# DDRSS0_CTL_CFG register map
Vendor: Texas Instruments
Peripheral module from a debugger description file (folder am65x).
Registers are 32-bit, read-write, reset 0x0 unless marked. A register's access mark holds for its fields unless they carry their own. Offsets are as the file gives them; lines under a group give offsets from that group; [hi:lo] are bit positions; {n}, {i} and the like mark numbered series; 'fields as' and 'values as' point back to an identical list; <NAME> marks a mode.

## DDRSS0_CTL_CFG (part 1 of 2)
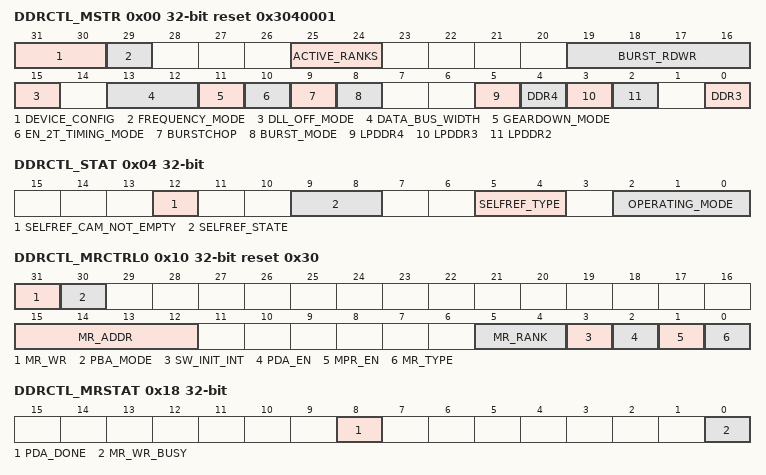
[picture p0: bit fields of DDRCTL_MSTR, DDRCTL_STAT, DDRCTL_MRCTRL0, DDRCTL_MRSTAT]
0x00 DDRCTL_MSTR reset 0x3040001 — Master Register0
  [31:30] DEVICE_CONFIG — Indicates the configuration of the device used in the system.
  [29] FREQUENCY_MODE — Choose which registers are used.1 - FREQ1 registersProgramming Mode: Quasi-dynamic Group 2
  [25:24] ACTIVE_RANKS — Only present for multi-rank configurations.LSB is the lowest rank number. For 2 ranks following combinations are legal:For 4 ranks following combinations are legal:
  [19:16] BURST_RDWR — SDRAM burst length used:
  [15] DLL_OFF_MODE — Set to 1 when the DDR controller and DRAM has to be put in DLL-off mode for low frequency operation.
  [13:12] DATA_BUS_WIDTH — Selects proportion of DQ bus width that is used by the SDRAM
  [11] GEARDOWN_MODE — 1 - Put the DRAM in geardown mode (2N)0 - Put the DRAM in normal mode (1N)This register can be changed, only when the Controller is in self-refresh mode. This signal must be set the same value as MR3 bit A3.
  [10] EN_2T_TIMING_MODE — If 1, then DDR controller uses 2T timing. Otherwise, uses 1T timing. In 2T timing, all command signals (except chip select) are held for 2 clocks on the SDRAM bus. Chip select is asserted on the second cycle of the command
  [9] BURSTCHOP — When set, enable burst-chop (BC4 or 8 on-the-fly) in DDR3/DDR4.
  [8] BURST_MODE — Indicates burst mode.
  [5] LPDDR4 — Select LPDDR4 SDRAM
  [4] DDR4 — Select DDR4 SDRAM
  [3] LPDDR3 — Select LPDDR3 SDRAM
  [2] LPDDR2 — Select LPDDR2 SDRAM
  [0] DDR3 — Select DDR3 SDRAM
0x04 DDRCTL_STAT ro — Operating Mode Status Register
  [12] SELFREF_CAM_NOT_EMPTY — Self refresh with CAMs not empty.
  [9:8] SELFREF_STATE — Self refresh state.
  [5:4] SELFREF_TYPE — Flags if Self Refresh (except LPDDR4) or SR-Powerdown (LPDDR4) is entered and if it was under Automatic Self Refresh control only or not.
  [2:0] OPERATING_MODE — Operating mode.mDDR/LPDDR2/LPDDR3 or DDR4 designs:LPDDR4 designs:
0x10 DDRCTL_MRCTRL0 access not given reset 0x30 — Mode Register Read/Write Control Register 0. Note: Do not enable more than one of the following fields simultaneously: - sw_init_int - pda_en - mpr_en
  [31] MR_WR — Setting this register bit to 1 triggers a mode register read or write operation. (access W1S)
  [30] PBA_MODE rw — Indicates whether PBA access is executed.
  [15:12] MR_ADDR rw — Address of the mode register that is to be written to.Don't Care for LPDDR2/LPDDR3/LPDDR4 (see DDRCTL_MRCTRL1.mr_data for mode register addressing in LPDDR2/LPDDR3/LPDDR4).This signal is also used for writing to control words of the register chip on RDIMMs/LRDIMMs. In that case, it corresponds to the bank address bits sent to the RDIMM/LRDIMM In case of DDR4, the bit [3:2] corresponds to the bank group bits. Therefore, the bit[3] as well as the bit [2:0] must be set to an appropriate value which is considered both the Address Mirroring of UDIMMs/RDIMMs/LRDIMMs and the Output Inversion of RDIMMs/LRDIMMs.
  [5:4] MR_RANK rw — Controls which rank is accessed by DDRCTL_MRCTRL0.mr_wr.Normally, it is desired to access all ranks, so all bits should be set to 1. However, for multi-rank UDIMMs/RDIMMs/LRDIMMs which implement address mirroring, it may be necessary to access ranks individually. Examples (assume DDR controller is configured for 4 ranks):
  [3] SW_INIT_INT rw — Indicates whether Software intervention is allowed via DDRCTL_MRCTRL0/DDRCTL_MRCTRL1 before automatic SDRAM initialization routine or not.
  [2] PDA_EN rw — Indicates whether the mode register operation is MRS in PDA mode or not
  [1] MPR_EN rw — Indicates whether the mode register operation is MRS or WR/RD for MPR (only supported for DDR4)
  [0] MR_TYPE rw — Indicates whether the mode register operation is read or write.
0x14 DDRCTL_MRCTRL1 — Mode Register Read/Write Control Register 1
  [17:0] MR_DATA — Mode register write data for all non-LPDDR2/non-LPDDR3/non-LPDDR4 modes.
0x18 DDRCTL_MRSTAT ro — Mode Register Read/Write Status Register
  [8] PDA_DONE — The SoC core may initiate a MR write operation in PDA/PBA mode only if this signal is low.
  [0] MR_WR_BUSY — The SoC core may initiate a MR write operation only if this signal is low.
0x1C DDRCTL_MRCTRL2 — Mode Register Read/Write Control Register 2
  [31:0] MR_DEVICE_SEL — Indicates the device(s) to be selected during the MRS that happens in PDA mode.
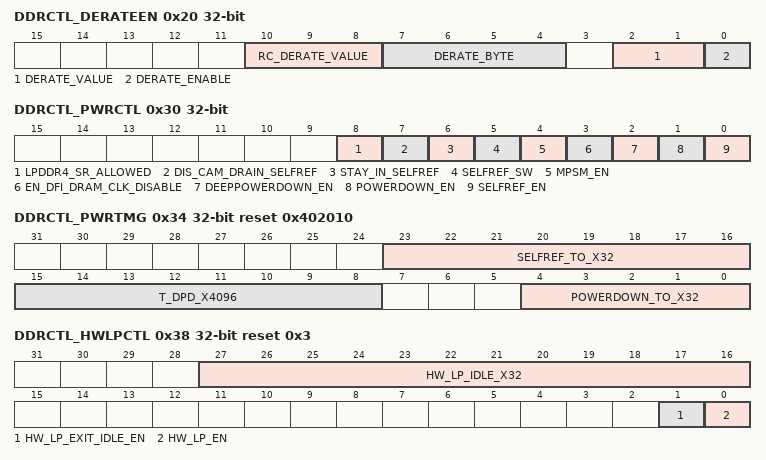
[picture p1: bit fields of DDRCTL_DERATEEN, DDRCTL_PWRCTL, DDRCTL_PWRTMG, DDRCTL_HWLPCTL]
0x20 DDRCTL_DERATEEN — Temperature Derate Enable Register
  [10:8] RC_DERATE_VALUE — Derate value of tRC for LPDDR4Present only in designs configured to support LPDDR4. The required number of cycles for derating can be determined by dividing 3.75ns by the core_ddrc_core_clk period, and rounding up the next integer.
  [7:4] DERATE_BYTE — Derate bytePresent only in designs configured to support LPDDR2/LPDDR3/LPDDR4Indicates which byte of the MRR data is used for derating.
  [2:1] DERATE_VALUE — Derate valuePresent only in designs configured to support LPDDR2/LPDDR3/LPDDR4 Set to 0 for all LPDDR2 speed grades as derating value of +1.875 ns is less than a core_ddrc_core_clk period. For LPDDR3/4, if the period of core_ddrc_core_clk is less than 1.875ns, this register field should be set to 1 otherwise it should be set to 0.
  [0] DERATE_ENABLE — Enables derating
0x24 DDRCTL_DERATEINT reset 0x800000 — Temperature Derate Interval Register
  [31:0] MR4_READ_INTERVAL — Interval between two MR4 reads, used to derate the timing parameters.
0x30 DDRCTL_PWRCTL — Low Power Control Register
  [8] LPDDR4_SR_ALLOWED — Indicates whether transition from SR-PD to SR and back to SR-PD is allowed.
  [7] DIS_CAM_DRAIN_SELFREF — Indicates whether skipping CAM draining is allowed when entering Self-Refresh.
  [6] STAY_IN_SELFREF — Self refresh state is an intermediate state to enter to Self refresh power down state or exit Self refresh power down state for LPDDR4.
  [5] SELFREF_SW — A value of 1 to this register causes system to move to Self Refresh state immediately, as long as it is not in INIT or DPD/MPSM operating_mode.
  [4] MPSM_EN — When this is 1, the DDR controller puts the SDRAM into maximum power saving mode when the transaction store is empty.
  [3] EN_DFI_DRAM_CLK_DISABLE — Enable the assertion of dfi_dram_clk_disable whenever a clock is not required by the SDRAM.In DDR2/DDR3, can only be asserted in Self Refresh.In DDR4, can be asserted in following:- in Self Refresh.- in Maximum Power Saving ModeIn mDDR/LPDDR2/LPDDR3, can be asserted in following:- in Self Refresh- in Power Down- in Deep Power Down- during Normal operation (Clock Stop)In LPDDR4, can be asserted in following:- in Self Refresh Power Down- in Power Down- during Normal operation (Clock Stop)
  [2] DEEPPOWERDOWN_EN — When this is 1, DDR controller puts the SDRAM into deep power-down mode when the transaction store is empty.For non-mDDR/non-LPDDR2/non-LPDDR3, this register should not be set to 1.
  [1] POWERDOWN_EN — If true then the DDR controller goes into power-down after a programmable number of cycles 'maximum idle clocks before power down' (DDRCTL_PWRTMG.powerdown_to_x32).This register bit may be re-programmed during the course of normal operation.
  [0] SELFREF_EN — If true then the DDR controller puts the SDRAM into Self Refresh after a programmable number of cycles 'maximum idle clocks before Self Refresh (DDRCTL_PWRTMG.selfref_to_x32)'.This register bit may be re-programmed during the course of normal operation.
0x34 DDRCTL_PWRTMG reset 0x402010 — Low Power Timing Register
  [23:16] SELFREF_TO_X32 — After this many clocks of the DDRC command channel being idle the DDR controller automatically puts the SDRAM into Self Refresh.
  [15:8] T_DPD_X4096 — Minimum deep power-down time.
  [4:0] POWERDOWN_TO_X32 — After this many clocks of the DDRC command channel being idle the DDR controller automatically puts the SDRAM into power-down.
0x38 DDRCTL_HWLPCTL reset 0x3 — Hardware Low Power Control Register
  [27:16] HW_LP_IDLE_X32 — Hardware idle period.
  [1] HW_LP_EXIT_IDLE_EN — When this bit is programmed to 1 the cactive_in_ddrc pin of the DDRC can be used to exit from the automatic clock stop, automatic power down or automatic self-refresh modes.
  [0] HW_LP_EN — Enable for Hardware Low Power Interface.
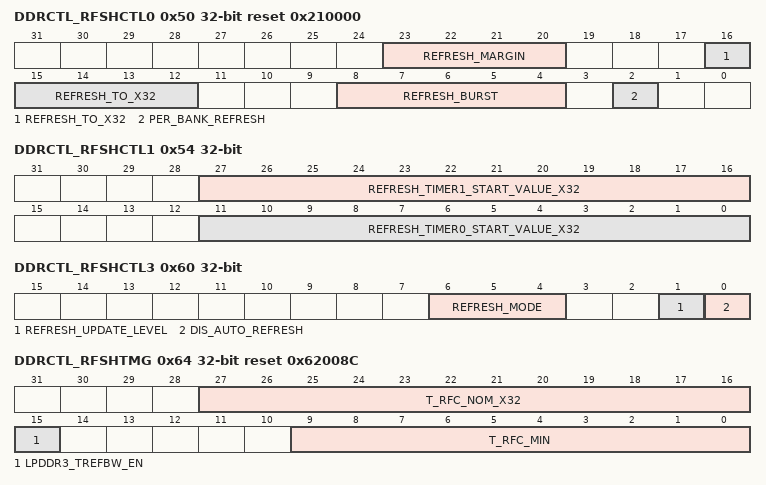
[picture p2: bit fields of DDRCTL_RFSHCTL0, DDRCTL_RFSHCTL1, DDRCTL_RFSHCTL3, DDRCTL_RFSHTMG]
0x50 DDRCTL_RFSHCTL0 reset 0x210000 — Refresh Control Register 0
  [23:20] REFRESH_MARGIN — Threshold value in number of DDRSS_CTL_CLK clock cycles before the critical refresh or page timer expires.
  [16:12] REFRESH_TO_X32 — If the refresh timer (tRFCnom, also known as tREFI) has expired at least once, but it has not expired (DDRCTL_RFSHCTL0.refresh_burst+1) times yet, then a speculative refresh may be performed. A speculative refresh is a refresh performed at a time when refresh would be useful, but before it is absolutely required.
  [8:4] REFRESH_BURST — The programmed value + 1 is the number of refresh timeouts that is allowed to accumulate before traffic is blocked and the refreshes are forced to execute.For information on burst refresh feature refer to section 3.9 of DDR2 JEDEC specification - JESD79-2F.pdf. For DDR2/3, the refresh is always per-rank and not per-bank. The rank refresh can be accumulated over 8*tREFI cycles using the burst refresh feature. In DDR4 mode, according to Fine Granularity feature, 8 refreshes can be postponed in 1X mode, 16 refreshes in 2X mode and 32 refreshes in 4X mode. If using PHY-initiated updates, care must be taken in the setting of DDRCTL_RFSHCTL0.refresh_burst, to ensure that tRFCmax is not violated due to a PHY-initiated update occurring shortly before a refresh burst was due. In this situation, the refresh burst will be delayed until the PHY-initiated update is complete.
  [2] PER_BANK_REFRESH — 1 - Per bank refresh
0x54 DDRCTL_RFSHCTL1 — Refresh Control Register 1
  [27:16] REFRESH_TIMER1_START_VALUE_X32 — Refresh timer start for rank 1 (only present in multi-rank configurations).
  [11:0] REFRESH_TIMER0_START_VALUE_X32 — Refresh timer start for rank 0 (only present in multi-rank configurations).
0x60 DDRCTL_RFSHCTL3 — Refresh Control Register 3
  [6:4] REFRESH_MODE — Fine Granularity Refresh Mode
  [1] REFRESH_UPDATE_LEVEL — Toggle this signal (either from 0 to 1 or from 1 to 0) to indicate that the refresh register(s) have been updated.
  [0] DIS_AUTO_REFRESH — When '1', disable auto-refresh generated by the DDR controller.
0x64 DDRCTL_RFSHTMG reset 0x62008C — Refresh Timing Register
  [27:16] T_RFC_NOM_X32 — tREFI: Average time interval between refreshes per rank (Specification: 7.8us for DDR2, DDR3 and DDR4. See JEDEC specification for mDDR, LPDDR2, LPDDR3 and LPDDR4).For LPDDR2/LPDDR3/LPDDR4:- if using all-bank refreshes (DDRCTL_RFSHCTL0.per_bank_refresh = 0), this register should be set to tREFIab- if using per-bank refreshes (DDRCTL_RFSHCTL0.per_bank_refresh = 1), this register should be set to tREFIpb
  [15] LPDDR3_TREFBW_EN — Used only when LPDDR3 memory type is connected.
  [9:0] T_RFC_MIN — tRFC (min): Minimum time from refresh to refresh or activate.In LPDDR2/LPDDR3/LPDDR4 mode:- if using all-bank refreshes, the tRFCmin value in the above equations is equal to tRFCab- if using per-bank refreshes, the tRFCmin value in the above equations is equal to tRFCpbIn DDR4 mode, the tRFCmin value in the above equations is different depending on the refresh mode (fixed 1X,2X,4X) and the device density. The user should program the appropriate value from the spec based on the 'refresh_mode' and the device density that is used. Unit: Clocks.
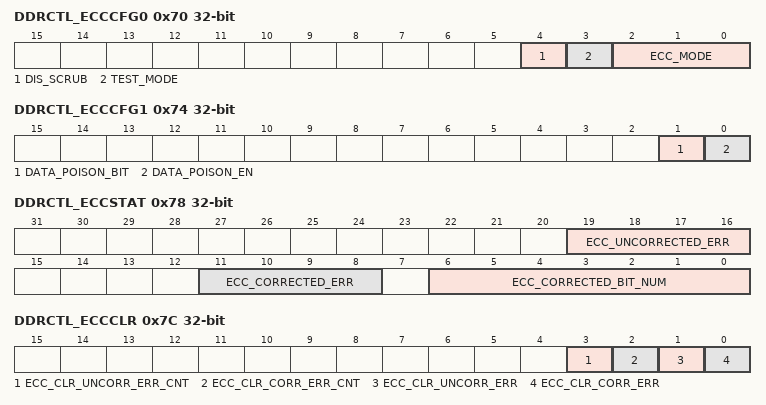
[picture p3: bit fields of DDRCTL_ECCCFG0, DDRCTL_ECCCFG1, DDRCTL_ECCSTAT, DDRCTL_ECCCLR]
0x70 DDRCTL_ECCCFG0 — ECC Configuration Register 0
  [4] DIS_SCRUB — Disable ECC scrubs.
  [3] TEST_MODE — If this bit is set to 1, no ECC is performed, and the ECC byte is accessed directly from co_wu_rxdata_ecc and ra_co_resp_ecc_data.
  [2:0] ECC_MODE — ECC mode indicator
0x74 DDRCTL_ECCCFG1 — ECC Configuration Register 1
  [1] DATA_POISON_BIT — Selects whether to poison 1 or 2 bitsif 0 -&gt; 2-bit (uncorrectable) data poisoning,if 1 -&gt; 1-bit (correctable) data poisoning, if DDRCTL_ECCCFG1.data_poison_en=1.Programming Mode: Quasi-dynamic Group 3
  [0] DATA_POISON_EN — Enable ECC data poisoning - introduces ECC errors on writes to address specified by the DDRCTL_ECCPOISONADDR0/1 registers
0x78 DDRCTL_ECCSTAT ro — SECDED ECC Status Register
  [19:16] ECC_UNCORRECTED_ERR — Double-bit error indicators.
  [11:8] ECC_CORRECTED_ERR — Single-bit error indicators.
  [6:0] ECC_CORRECTED_BIT_NUM — Bit number corrected by single-bit ECC error.
0x7C DDRCTL_ECCCLR access not given — ECC Clear Register
  [3] ECC_CLR_UNCORR_ERR_CNT — Setting this register bit to 1 clears the currently stored uncorrected ECC error count. (access RW1C)
  [2] ECC_CLR_CORR_ERR_CNT — Setting this register bit to 1 clears the currently stored corrected ECC error count. (access RW1C)
  [1] ECC_CLR_UNCORR_ERR — Setting this register bit to 1 clears the currently stored uncorrected ECC error. (access RW1C)
  [0] ECC_CLR_CORR_ERR — Setting this register bit to 1 clears the currently stored corrected ECC error. (access RW1C)
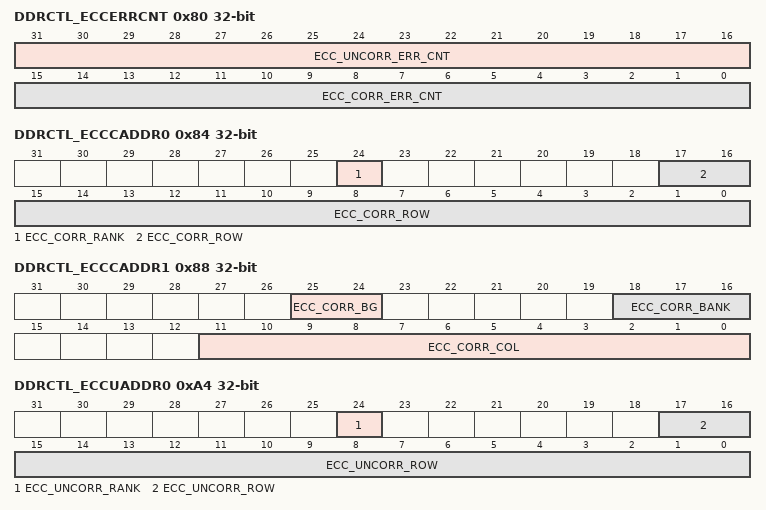
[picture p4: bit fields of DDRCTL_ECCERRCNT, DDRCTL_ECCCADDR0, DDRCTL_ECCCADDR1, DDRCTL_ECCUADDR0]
0x80 DDRCTL_ECCERRCNT ro — ECC Error Counter Register
  [31:16] ECC_UNCORR_ERR_CNT — Number of uncorrectable ECC errors detected.
  [15:0] ECC_CORR_ERR_CNT — Number of correctable ECC errors detected.
0x84 DDRCTL_ECCCADDR0 ro — ECC Corrected Error Address Register 0
  [24] ECC_CORR_RANK — Rank number of a read resulting in a corrected ECC error
  [17:0] ECC_CORR_ROW — Page/row number of a read resulting in a corrected ECC error.
0x88 DDRCTL_ECCCADDR1 ro — ECC Corrected Error Address Register 1
  [25:24] ECC_CORR_BG — Bank Group number of a read resulting in a corrected ECC error
  [18:16] ECC_CORR_BANK — Bank number of a read resulting in a corrected ECC error
  [11:0] ECC_CORR_COL — Block number of a read resulting in a corrected ECC error (lowest bit not assigned here)
0x8C DDRCTL_ECCCSYN0 ro — ECC Corrected Syndrome Register 0
  [31:0] ECC_CORR_SYNDROMES_31_0 — Data pattern that resulted in a corrected error.
0x94 DDRCTL_ECCCSYN2 ro — ECC Corrected Syndrome Register 2
  [7:0] ECC_CORR_SYNDROMES_71_64 — Data pattern that resulted in a corrected error one for each ECC lane, all concatenated together This register refers to the ECC byte, which is bits [71:64] for 64-bit ECC, [39:32] for 32-bit ECC, or [23:16] for 16-bit ECC
0x98 DDRCTL_ECCBITMASK0 ro — ECC Corrected Data Bit Mask Register 0
  [31:0] ECC_CORR_BIT_MASK_31_0 — Mask for the corrected data portion1 on any bit indicates that the bit has been corrected by the ECC logic0 on any bit indicates that the bit has not been corrected by the ECC logicThis register accumulates data over multiple ECC errors, to give an overall indication of which bits are being fixed.
0xA0 DDRCTL_ECCBITMASK2 ro — ECC Corrected Data Bit Mask Register 2
  [7:0] ECC_CORR_BIT_MASK_71_64 — Mask for the corrected data portion1 on any bit indicates that the bit has been corrected by the ECC logic0 on any bit indicates that the bit has not been corrected by the ECC logicThis register accumulates data over multiple ECC errors, to give an overall indication of which bits are being fixed.
0xA4 DDRCTL_ECCUADDR0 ro — ECC Uncorrected Error Address Register 0
  [24] ECC_UNCORR_RANK — Rank number of a read resulting in an uncorrected ECC error
  [17:0] ECC_UNCORR_ROW — Page/row number of a read resulting in an uncorrected ECC error.
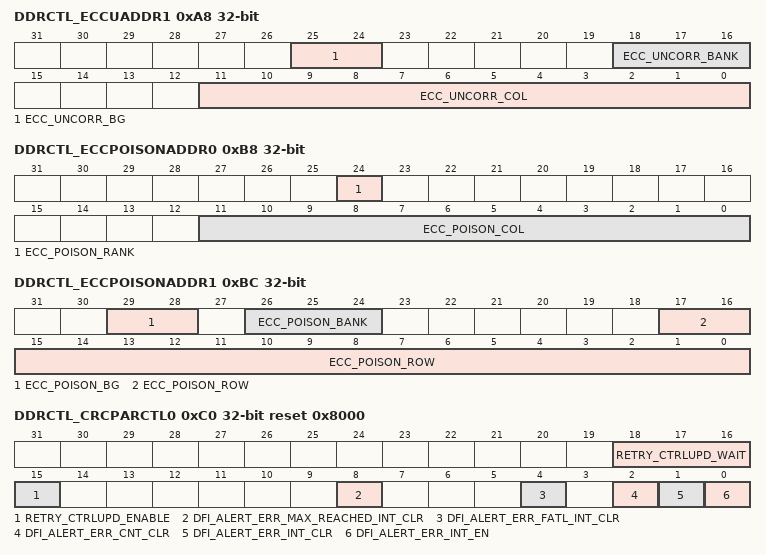
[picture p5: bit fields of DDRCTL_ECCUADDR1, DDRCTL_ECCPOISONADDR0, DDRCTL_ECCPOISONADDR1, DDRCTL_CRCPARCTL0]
0xA8 DDRCTL_ECCUADDR1 ro — ECC Uncorrected Error Address Register 1
  [25:24] ECC_UNCORR_BG — Bank Group number of a read resulting in an uncorrected ECC error
  [18:16] ECC_UNCORR_BANK — Bank number of a read resulting in an uncorrected ECC error
  [11:0] ECC_UNCORR_COL — Block number of a read resulting in an uncorrected ECC error (lowest bit not assigned here)
0xAC DDRCTL_ECCUSYN0 ro — ECC Uncorrected Syndrome Register 0
  [31:0] ECC_UNCORR_SYNDROMES_31_0 — Data pattern that resulted in an uncorrected error, one for each ECC lane, all concatenated together.
0xB4 DDRCTL_ECCUSYN2 ro — ECC Uncorrected Syndrome Register 2
  [7:0] ECC_UNCORR_SYNDROMES_71_64 — Data pattern that resulted in an uncorrected error one for each ECC lane, all concatenated together.
0xB8 DDRCTL_ECCPOISONADDR0 — ECC Data Poisoning Address Register 0. If a HIF write data beat matches the address specified in this register, an ECC error will be introduced on that transaction (write/RMW), if DDRCTL_ECCCFG1.data_poison_en=1
  [24] ECC_POISON_RANK — Rank address for ECC poisoning
  [11:0] ECC_POISON_COL — Column address for ECC poisoning.- In full bus width mode, ecc_poison_col [2:0] must be set to 0- In half bus width mode, ecc_poison_col [3:0] must be set to 0- In quarter bus width mode, ecc_poison_col [4:0] must be set to 0
0xBC DDRCTL_ECCPOISONADDR1 — ECC Data Poisoning Address Register 1. If a HIF write data beat matches the address specified in this register, an ECC error will be introduced on that transaction (write/RMW), if DDRCTL_ECCCFG1.data_poison_en=1
  [29:28] ECC_POISON_BG — Bank Group address for ECC poisoning
  [26:24] ECC_POISON_BANK — Bank address for ECC poisoning
  [17:0] ECC_POISON_ROW — Row address for ECC poisoning.
0xC0 DDRCTL_CRCPARCTL0 access not given reset 0x8000 — CRC Parity Control Register0
  [18:16] RETRY_CTRLUPD_WAIT rw — Additional wait time after dfi_ctrlupd_req for retry has occurred to ensure PHY's internals (FIFO pointers) have been reset correctly.
  [15] RETRY_CTRLUPD_ENABLE rw — dfi_ctrlupd_req enable for retry.0 - Disable to issue dfi_ctrlupd_req before starting retry sequenceThe DFI controller update can be used to reset PHY FIFO pointers. If both DDRCTL_CRCPARCTL0.retry_cfrlupd_enable and DDRCTL_CRCPARCTL1.alert_wait_for_sw are enabled, dfi_ctrlupd_req is issued just before software intervention time. If DDRCTL_CRCPARCTL0.retry_cfrlupd_enable is enabled, dfi_ctrlupd_req will be issued regardless of DDRCTL_DFIUPD0.dis_auto_ctrlupd.
  [8] DFI_ALERT_ERR_MAX_REACHED_INT_CLR — Interrupt clear bit for DFI alert counter saturation. (access RW1C)
  [4] DFI_ALERT_ERR_FATL_INT_CLR — Interrupt clear bit for dfi_alert_err_fatl_int. (access RW1C)
  [2] DFI_ALERT_ERR_CNT_CLR — DFI alert error count clear. (access RW1C)
  [1] DFI_ALERT_ERR_INT_CLR — Interrupt clear bit for DFI alert error. (access RW1C)
  [0] DFI_ALERT_ERR_INT_EN rw — Interrupt enable bit for DFI alert error.
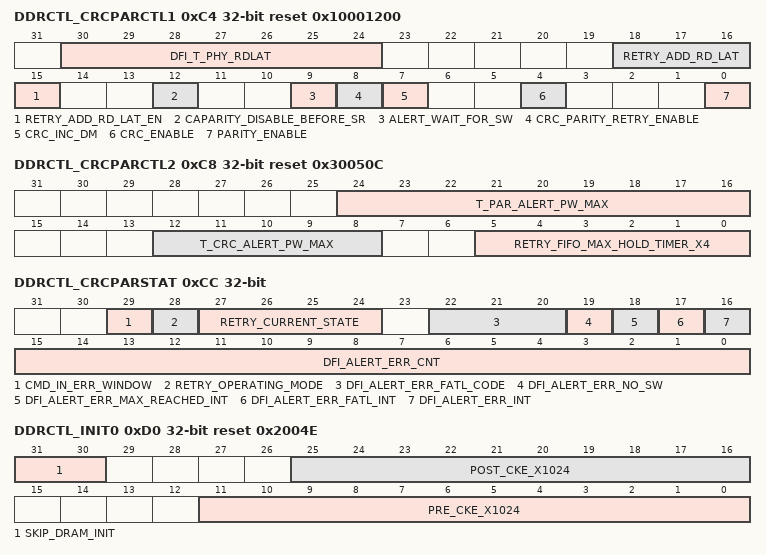
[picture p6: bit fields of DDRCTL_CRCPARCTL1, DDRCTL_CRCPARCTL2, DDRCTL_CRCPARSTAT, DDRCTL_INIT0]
0xC4 DDRCTL_CRCPARCTL1 reset 0x10001200 — CRC Parity Control Register1
  [30:24] DFI_T_PHY_RDLAT — The maximum time allowed from the assertion of the dfi_rddata_en signal to the assertion of each of the corresponding bits of the dfi_rddata_valid signal.
  [18:16] RETRY_ADD_RD_LAT — Retry additional read latency value.
  [15] RETRY_ADD_RD_LAT_EN — Retry additional read latency enable.
  [12] CAPARITY_DISABLE_BEFORE_SR — If DDR4-SDRAM's CA parity is enabled by DDRCTL_INIT6.mr5 [2:0]!=0 and this register is set to 1, CA parity is automatically disabled before Self-Refresh entry and enabled after Self-Refresh exit by issuing MR5.1 - CA parity is disabled before Self-Refresh entry0 - CA parity is not disabled before Self-Refresh entryIf Geardown is used by DDRCTL_MSTR.geardown_mode=1, this register must be set to 1.If this register set to 0, DDRCTL_DRAMTMG5.t_ckesr and DDRCTL_DRAMTMG5.t_cksre must be increased by PL(Parity latency)
  [9] ALERT_WAIT_FOR_SW — After a Parity or CRC error is flagged on dfi_alert_n signal, the software has an option to read the mode registers in the DRAM before the hardware begins the retry process1 - Wait for software to read/write the mode registers before hardware begins the retry. After software is done with its operations, it will clear the alert interrupt register bit0 - Hardware can begin the retry right away after the dfi_alert_n pulse goes away.The value on this register is valid only when retry is enabled (CRCPARCTRL.crc_parity_retry_enable = 1). If this register is set to 1 and if the software doesn't clear the interrupt register after handling the parity/CRC error, then the hardware will not begin the retry process and the system will hang. In the case of Parity/CRC error, there are two possibilities when the software doesn't reset MR5[4] to 0.- (i) If 'Persistent parity' mode register bit is NOT set: the commands sent during retry and normal operation are executed without parity checking. The value in the Parity error log register MPR Page 1 is valid.- (ii) If 'Persistent parity' mode register bit is SET: Parity checking is done for commands sent during retry and normal operation. If multiple errors occur before MR5[4] is cleared, the error log in MPR Page 1 should be treated as 'Don't care'.
  [8] CRC_PARITY_RETRY_ENABLE — 1 - Enable command retry mechanism in case of C/A Parity or CRC error0 - Disable command retry mechanism when C/A Parity or CRC features are enabled.
  [7] CRC_INC_DM — CRC Calculation setting register1 - CRC includes DM signal0 - CRC not includes DM signal Present only in designs configured to support DDR4.
  [4] CRC_ENABLE — CRC enable Register1 - Enable generation of CRC0 - Disable generation of CRC The setting of this register should match the CRC mode register setting in the DRAM.
  [0] PARITY_ENABLE — C/A Parity enable register1 - Enable generation of C/A parity and detection of C/A parity error0 - Disable generation of C/A parity and disable detection of C/A parity error If RCD's parity error detection or SDRAM's parity detection is enabled, this register should be 1.
0xC8 DDRCTL_CRCPARCTL2 reset 0x30050C — CRC Parity Control Register2
  [24:16] T_PAR_ALERT_PW_MAX — Value from the DRAM spec indicating the maximum width of the dfi_alert_n pulse when a parity error occurs.
  [12:8] T_CRC_ALERT_PW_MAX — Value from the DRAM spec indicating the maximum width of the dfi_alert_n pulse when a CRC error occurs.
  [5:0] RETRY_FIFO_MAX_HOLD_TIMER_X4 — Indicates the maximum duration in number of DRAM clock cycles for which a command should be held in the Command Retry FIFO before it is popped out.Recommended(minimum) values:- Only C/A Parity is enabled. RoundUp((PHY Command Latency(DRAM CLK) + CAL + RCD delay + tPAR_ALERT_ON.max + tPAR_UNKNOWN + PHY Alert Latency(DRAM CLK) + board delay + PHY's max granularity of dfi_rddata beats that may be corrupted before erroneous Read) / 4) + 2- Only CRC is enabled. RoundUp((PHY Command Latency(DRAM CLK) + CAL + RCD delay + WL + 5(BL10)+ tCRC_ALERT.max + PHY Alert Latency(DRAM CLK) + board delay) / 4) + 2- If both C/A Parity and CRC are enabled, use max of (Only C/A Parity is enabled, Only CRC is enabled)
0xCC DDRCTL_CRCPARSTAT ro — CRC Parity Status Register
  [29] CMD_IN_ERR_WINDOW — Indicate if commands are in the parity/crc error window.
  [28] RETRY_OPERATING_MODE — Operating mode of retry
  [27:24] RETRY_CURRENT_STATE — Indicate current retry state for debug purposes only
  [22:20] DFI_ALERT_ERR_FATL_CODE — Indicate reason of dfi_alert_err_fatl_int assertion- [22] MPSMX caused parity error.(RCD's parity error detection only)- [21] Parity error happens again during software intervention time- [20] MRS was in retry_fifo_max_hold_timer_x4 window from alert_n=0 or DDRCTL_STAT.operating_mode is Init. Two or more reason can be available at the same time It remains set until cleared by DDRCTL_CRCPARCTL0.dfi_alert_err_fatl_clr.
  [19] DFI_ALERT_ERR_NO_SW — Indicate whether software can perform MRS/MPR/PDA during software intervention time.
  [18] DFI_ALERT_ERR_MAX_REACHED_INT — DFI alert error counter max reached interrupt.
  [17] DFI_ALERT_ERR_FATL_INT — Fatal parity error interrupt.- MPSMX caused parity error. (RCD's parity error detection only)- Parity error happens again during software intervention time- MRS was in retry_fifo_max_hold_timer_x4 window from alert_n=0 or DDRCTL_STAT.operating_mode is Init. It remains set until cleared by DDRCTL_CRCPARCTL0.dfi_alert_err_fatl_clr. If this interrupt is asserted, system reset is strongly recommended.
  [16] DFI_ALERT_ERR_INT — DFI alert error interrupt.
  [15:0] DFI_ALERT_ERR_CNT — DFI alert error count.
0xD0 DDRCTL_INIT0 reset 0x2004E — SDRAM Initialization Register 0
  [31:30] SKIP_DRAM_INIT — If lower bit is enabled the SDRAM initialization routine is skipped.
  [25:16] POST_CKE_X1024 — Cycles to wait after driving CKE high to start the SDRAM initialization sequence.
  [11:0] PRE_CKE_X1024 — Cycles to wait after reset before driving CKE high to start the SDRAM initialization sequence.
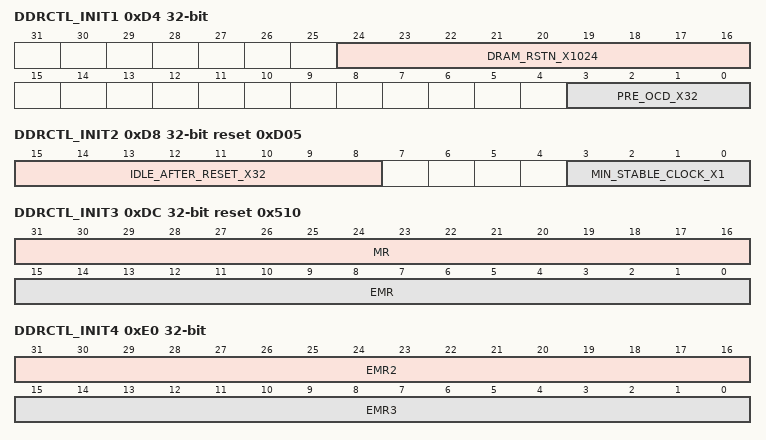
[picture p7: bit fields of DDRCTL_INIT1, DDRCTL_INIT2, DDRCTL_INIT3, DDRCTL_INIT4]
0xD4 DDRCTL_INIT1 — SDRAM Initialization Register 1
  [24:16] DRAM_RSTN_X1024 — Number of cycles to assert SDRAM reset signal during init sequence.
  [3:0] PRE_OCD_X32 — Wait period before driving the OCD complete command to SDRAM.
0xD8 DDRCTL_INIT2 reset 0xD05 — SDRAM Initialization Register 2
  [15:8] IDLE_AFTER_RESET_X32 — Idle time after the reset command, tINIT4.
  [3:0] MIN_STABLE_CLOCK_X1 — Time to wait after the first CKE high, tINIT2.
0xDC DDRCTL_INIT3 reset 0x510 — SDRAM Initialization Register 3
  [31:16] MR — DDR2: Value to write to MR register.DDR3/DDR4: Value loaded into MR0 register.mDDR: Value to write to MR register.LPDDR2/LPDDR3/LPDDR4 - Value to write to MR1 register
  [15:0] EMR — DDR2: Value to write to EMR register.DDR3/DDR4: Value to write to MR1 register Set bit 7 to 0. If PHY-evaluation mode training is enabled, this bit is set appropriately by the DDR controller during write leveling.mDDR: Value to write to EMR register.LPDDR2/LPDDR3/LPDDR4 - Value to write to MR2 register
0xE0 DDRCTL_INIT4 — SDRAM Initialization Register 4
  [31:16] EMR2 — DDR2: Value to write to EMR2 register.LPDDR2/LPDDR3/LPDDR4: Value to write to MR3 registermDDR: Unused
  [15:0] EMR3 — DDR2: Value to write to EMR3 register.mDDR/LPDDR2/LPDDR3: UnusedLPDDR4: Value to write to MR13 register
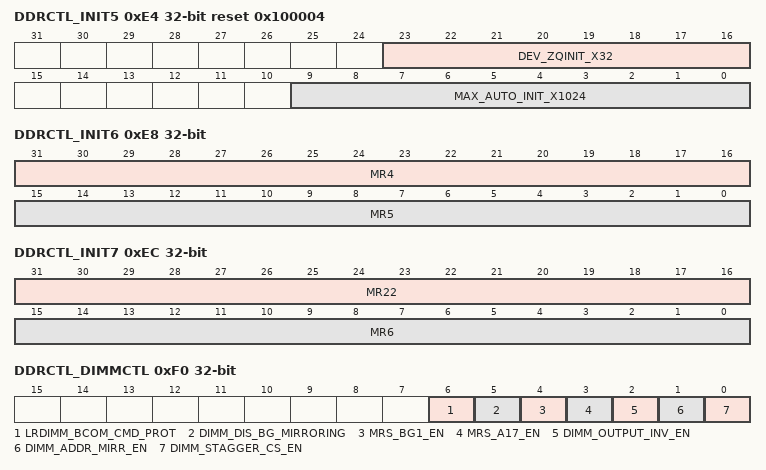
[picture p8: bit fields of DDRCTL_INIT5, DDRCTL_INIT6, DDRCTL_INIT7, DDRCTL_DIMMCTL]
0xE4 DDRCTL_INIT5 reset 0x100004 — SDRAM Initialization Register 5
  [23:16] DEV_ZQINIT_X32 — ZQ initial calibration, tZQINIT.
  [9:0] MAX_AUTO_INIT_X1024 — Maximum duration of the auto initialization, tINIT5.
0xE8 DDRCTL_INIT6 — SDRAM Initialization Register 6
  [31:16] MR4 — DDR4- Value to be loaded into SDRAM MR4 registers.
  [15:0] MR5 — DDR4- Value to be loaded into SDRAM MR5 registers.
0xEC DDRCTL_INIT7 — SDRAM Initialization Register 7
  [31:16] MR22 — LPDDR4- Value to be loaded into SDRAM MR22 registers.
  [15:0] MR6 — DDR4- Value to be loaded into SDRAM MR6 registers.
0xF0 DDRCTL_DIMMCTL — DIMM Control Register
  [6] LRDIMM_BCOM_CMD_PROT — Protects the timing restrictions (tBCW/tMRC) between consecutive BCOM commands defined in the Data Buffer specification.
  [5] DIMM_DIS_BG_MIRRORING — Disabling Address Mirroring for BG bits.
  [4] MRS_BG1_EN — Enable for BG1 bit of MRS command.
  [3] MRS_A17_EN — Enable for A17 bit of MRS command.
  [2] DIMM_OUTPUT_INV_EN — Output Inversion Enable (for DDR4 RDIMM/LRDIMM implementations only).
  [1] DIMM_ADDR_MIRR_EN — Address Mirroring Enable (for multi-rank UDIMM implementations and multi-rank DDR4 RDIMM/LRDIMM implementations).
  [0] DIMM_STAGGER_CS_EN — Staggering enable for multi-rank accesses (for multi-rank UDIMM, RDIMM and LRDIMM implementations only).
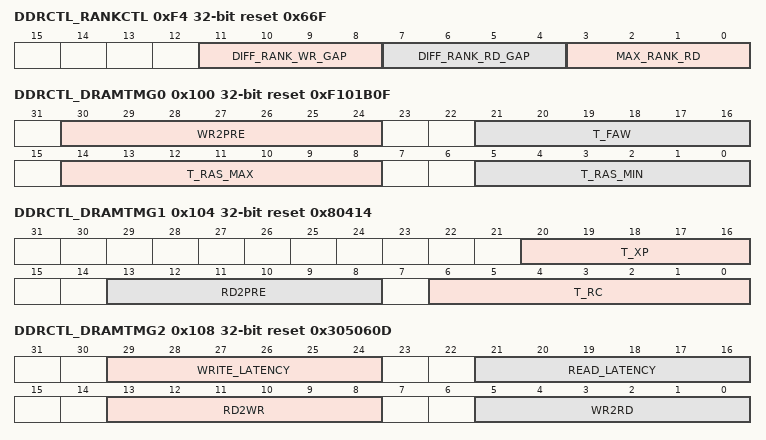
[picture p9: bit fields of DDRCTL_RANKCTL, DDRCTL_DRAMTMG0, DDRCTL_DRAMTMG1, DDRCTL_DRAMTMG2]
0xF4 DDRCTL_RANKCTL reset 0x66F — Rank Control Register
  [11:8] DIFF_RANK_WR_GAP — Only present for multi-rank configurations.- PHY requirement: tphy_wrcsgap If CRC feature is enabled, should be increased by 1. If write preamble is set to 2tCK(DDR4 only), should be increased by 1. If write postamble is set to 1.5tCK(LPDDR4 only), should be increased by 1.- ODT requirement: The value programmed in this register takes care of the ODT switch off timing requirement when switching ranks during writes. For LPDDR4, the requirement is ODTLoff - ODTLon - BL/2 + 1
  [7:4] DIFF_RANK_RD_GAP — Only present for multi-rank configurations.- PHY requirement: tphy_rdcsgap If read preamble is set to 2tCK(DDR4 only), should be increased by 1. If read postamble is set to 1.5tCK(LPDDR4 only), should be increased by 1.- ODT requirement: The value programmed in this register takes care of the ODT switch off timing requirement when switching ranks during reads.
  [3:0] MAX_RANK_RD — Only present for multi-rank configurations.
0x100 DDRCTL_DRAMTMG0 reset 0xF101B0F — SDRAM Timing Register 0
  [30:24] WR2PRE — Minimum time between write and precharge to same bank.Specifications: WL + BL/2 + tWR = approximately 8 cycles + 15 ns = 14 clocks MHz and less for lower frequencies where:- WL = write latency- BL = burst length. This must match the value programmed in the BL bit of the mode register to the SDRAM. BST (burst terminate) is not supported at present.- tWR = Write recovery time. This comes directly from the SDRAM specification. Add one extra cycle for LPDDR2/LPDDR3/LPDDR4 for this parameter.
  [21:16] T_FAW — tFAW Valid only when 8 or more banks(or banks x bank groups) are present.
  [14:8] T_RAS_MAX — tRAS(max): Maximum time between activate and precharge to same bank.
  [5:0] T_RAS_MIN — tRAS(min): Minimum time between activate and precharge to the same bank.
0x104 DDRCTL_DRAMTMG1 reset 0x80414 — SDRAM Timing Register 1
  [20:16] T_XP — tXP: Minimum time after power-down exit to any operation.
  [13:8] RD2PRE — tRTP: Minimum time from read to precharge of same bank.
  [6:0] T_RC — tRC: Minimum time between activates to same bank.
0x108 DDRCTL_DRAMTMG2 reset 0x305060D — SDRAM Timing Register 2
  [29:24] WRITE_LATENCY — Set to WL Time from write command to write data on SDRAM interface.
  [21:16] READ_LATENCY — Set to RL Time from read command to read data on SDRAM interface.
  [13:8] RD2WR — DDR2/3/mDDR: RL + BL/2 + 2 - WLDDR4: RL + BL/2 + 1 + WR_PREAMBLE - WLLPDDR2/LPDDR3: RL + BL/2 + RU(tDQSCKmax/tCK) + 1 - WLLPDDR4(DQ ODT is Disabled): RL + BL/2 + RU(tDQSCKmax/tCK) + WR_PREAMBLE + RD_POSTAMBLE - WLLPDDR4(DQ ODT is Enabled) : RL + BL/2 + RU(tDQSCKmax/tCK) + RD_POSTAMBLE - ODTLon - RU(tODTon(min)/tCK) Minimum time from read command to write command.- WL = write latency- BL = burst length. This must match the value programmed in the BL bit of the mode register to the SDRAM- RL = read latency = CAS latency- WR_PREAMBLE = write preamble. This is unique to DDR4 and LPDDR4.- RD_POSTAMBLE = read postamble. This is unique to LPDDR4. For LPDDR2/LPDDR3/LPDDR4, if derating is enabled (DDRCTL_DERATEEN.derate_enable=1), derated tDQSCKmax should be used.
  [5:0] WR2RD — DDR4: CWL + PL + BL/2 + tWTR_LLPDDR2/3/4: WL + BL/2 + tWTR + 1Others: CWL + BL/2 + tWTRIn DDR4, minimum time from write command to read command for same bank group.- CWL = CAS write latency- WL = Write latency- PL = Parity latency- BL = burst length. This must match the value programmed in the BL bit of the mode register to the SDRAM- tWTR_L = internal write to read command delay for same bank group. This comes directly from the SDRAM specification.- tWTR = internal write to read command delay. This comes directly from the SDRAM specification. Add one extra cycle for LPDDR2/LPDDR3/LPDDR4 operation.
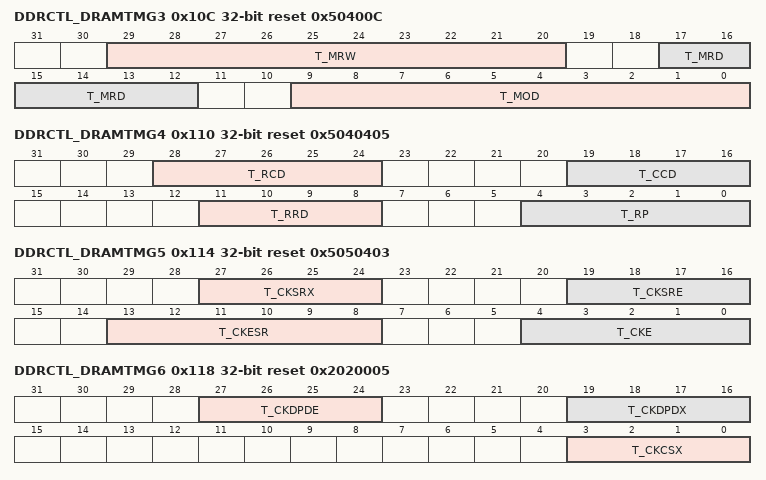
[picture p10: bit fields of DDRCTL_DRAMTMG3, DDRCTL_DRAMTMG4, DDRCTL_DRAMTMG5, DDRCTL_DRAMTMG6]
0x10C DDRCTL_DRAMTMG3 reset 0x50400C — SDRAM Timing Register 3
  [29:20] T_MRW — Time to wait after a mode register write or read (MRW or MRR).LPDDR2 typically requires value of 5.LPDDR3 typically requires value of 10.LPDDR4: Set this to the larger of tMRW and tMRWCKEL.For LPDDR2, this register is used for the time from a MRW/MRR to all other commands.
  [17:12] T_MRD — tMRD: Cycles to wait after a mode register write or read.
  [9:0] T_MOD — tMOD: Parameter used only in DDR3 and DDR4.
0x110 DDRCTL_DRAMTMG4 reset 0x5040405 — SDRAM Timing Register 4
  [28:24] T_RCD — tRCD - tAL: Minimum time from activate to read or write command to same bank.
  [19:16] T_CCD — DDR4: tCCD_L: This is the minimum time between two reads or two writes for same bank group.
  [11:8] T_RRD — DDR4: tRRD_L: Minimum time between activates from bank 'a' to bank 'b' for same bank group.
  [4:0] T_RP — tRP: Minimum time from precharge to activate of same bank.
0x114 DDRCTL_DRAMTMG5 reset 0x5050403 — SDRAM Timing Register 5
  [27:24] T_CKSRX — This is the time before Self Refresh Exit that CK is maintained as a valid clock before issuing SRX.
  [19:16] T_CKSRE — This is the time after Self Refresh Down Entry that CK is maintained as a valid clock.(*)Only if DDRCTL_CRCPARCTL1.caparity_disable_before_sr=0, this register should be increased by PL.
  [13:8] T_CKESR — Minimum CKE low width for Self refresh or Self refresh power down entry to exit timing in memory clock cycles.(*)Only if DDRCTL_CRCPARCTL1.caparity_disable_before_sr=0, this register should be increased by PL.
  [4:0] T_CKE — Minimum number of cycles of CKE HIGH/LOW during power-down and self refresh.
0x118 DDRCTL_DRAMTMG6 reset 0x2020005 — SDRAM Timing Register 6
  [27:24] T_CKDPDE — This is the time after Deep Power Down Entry that CK is maintained as a valid clock.
  [19:16] T_CKDPDX — This is the time before Deep Power Down Exit that CK is maintained as a valid clock before issuing DPDX.
  [3:0] T_CKCSX — This is the time before Clock Stop Exit that CK is maintained as a valid clock before issuing Clock Stop Exit.
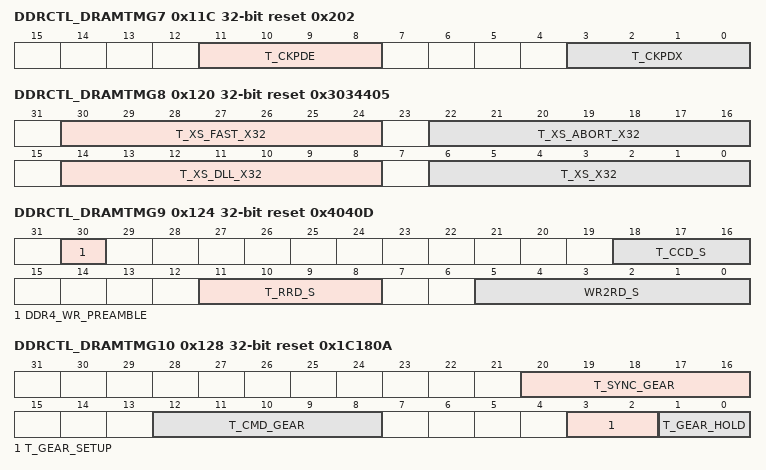
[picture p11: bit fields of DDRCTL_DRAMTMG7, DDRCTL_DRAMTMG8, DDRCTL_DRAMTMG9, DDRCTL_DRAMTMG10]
0x11C DDRCTL_DRAMTMG7 reset 0x202 — SDRAM Timing Register 7
  [11:8] T_CKPDE — This is the time after Power Down Entry that CK is maintained as a valid clock.
  [3:0] T_CKPDX — This is the time before Power Down Exit that CK is maintained as a valid clock before issuing PDX.
0x120 DDRCTL_DRAMTMG8 reset 0x3034405 — SDRAM Timing Register 8
  [30:24] T_XS_FAST_X32 — tXS_FAST: Exit Self Refresh to ZQCL, ZQCS and MRS (only CL, WR, RTP and Geardown mode).
  [22:16] T_XS_ABORT_X32 — tXS_ABORT: Exit Self Refresh to commands not requiring a locked DLL in Self Refresh Abort.
  [14:8] T_XS_DLL_X32 — tXSDLL: Exit Self Refresh to commands requiring a locked DLL.
  [6:0] T_XS_X32 — tXS: Exit Self Refresh to commands not requiring a locked DLL.
0x124 DDRCTL_DRAMTMG9 reset 0x4040D — SDRAM Timing Register 9
  [30] DDR4_WR_PREAMBLE — DDR4 Write preamble mode0 - 1tCK preamble1 - 2tCK preambleProgramming Mode: Quasi-dynamic Group 2 and Group 4
  [18:16] T_CCD_S — tCCD_S: This is the minimum time between two reads or two writes for different bank group.
  [11:8] T_RRD_S — tRRD_S: Minimum time between activates from bank 'a' to bank 'b' for different bank group.
  [5:0] WR2RD_S — CWL + PL + BL/2 + tWTR_S Minimum time from write command to read command for different bank group.- CWL = CAS write latency- PL = Parity latency- BL = burst length. This must match the value programmed in the BL bit of the mode register to the SDRAM- tWTR_S = internal write to read command delay for different bank group. This comes directly from the SDRAM specification.
0x128 DDRCTL_DRAMTMG10 reset 0x1C180A — SDRAM Timing Register 10
  [20:16] T_SYNC_GEAR — Indicates the time between MRS command and the sync pulse time.
  [12:8] T_CMD_GEAR — Sync pulse to first valid command.
  [3:2] T_GEAR_SETUP — Geardown setup time.
  [1:0] T_GEAR_HOLD — Geardown hold time.
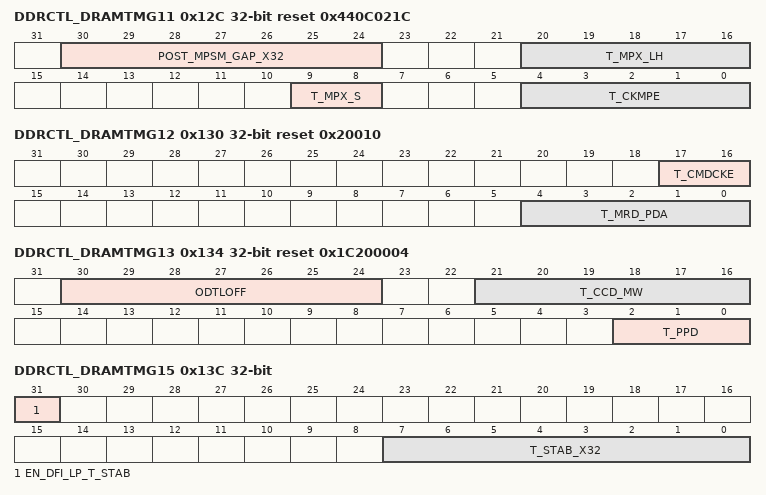
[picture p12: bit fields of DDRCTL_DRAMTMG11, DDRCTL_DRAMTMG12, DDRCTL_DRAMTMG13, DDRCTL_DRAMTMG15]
0x12C DDRCTL_DRAMTMG11 reset 0x440C021C — SDRAM Timing Register 11
  [30:24] POST_MPSM_GAP_X32 — tXMPDLL: This is the minimum Exit MPSM to commands requiring a locked DLL.
  [20:16] T_MPX_LH — tMPX_LH: This is the minimum CS_n Low hold time to CKE rising edge.
  [9:8] T_MPX_S — tMPX_S: Minimum time CS setup time to CKE.
  [4:0] T_CKMPE — tCKMPE: Minimum valid clock requirement after MPSM entry.
0x130 DDRCTL_DRAMTMG12 reset 0x20010 — SDRAM Timing Register 12
  [17:16] T_CMDCKE — tCMDCKE: Delay from valid command to CKE input LOW.
  [4:0] T_MRD_PDA — tMRD_PDA: This is the Mode Register Set command cycle time in PDA mode.
0x134 DDRCTL_DRAMTMG13 reset 0x1C200004 — SDRAM Timing Register 13
  [30:24] ODTLOFF — LPDDR4: tODTLoff: This is the latency from CAS-2 command to tODToff reference.
  [21:16] T_CCD_MW — LPDDR4: tCCDMW: This is the minimum time from write or masked write to masked write command for same bank.
  [2:0] T_PPD — LPDDR4: tPPD: This is the minimum time from precharge to precharge command.
0x138 DDRCTL_DRAMTMG14 reset 0xA0 — SDRAM Timing Register 14
  [11:0] T_XSR — tXSR: Exit Self Refresh to any command.
0x13C DDRCTL_DRAMTMG15 — SDRAM Timing Register 15
  [31] EN_DFI_LP_T_STAB — 1 - Enable using tSTAB when exiting DFI LP. Needs to be set when the PHY is stopping the clock during DFI LP to save maximum power.
  [7:0] T_STAB_X32 — tSTAB: Stabilization time.- when exiting power saving mode, if the clock was stopped, after re-enabling it the clock must be stable for a time specified by tSTAB- in the case of input clock frequency change (DDR4)- after issuing control words that refers to clock timing (Specification: 6us for DDR3, 5us for DDR4)
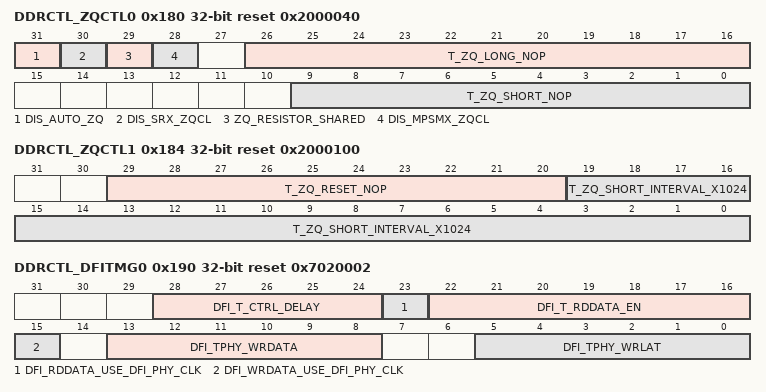
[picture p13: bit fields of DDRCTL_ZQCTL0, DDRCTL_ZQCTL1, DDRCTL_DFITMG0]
0x180 DDRCTL_ZQCTL0 reset 0x2000040 — ZQ Control Register 0
  [31] DIS_AUTO_ZQ — 1 - Disable DDR controller generation of ZQCS/MPC(ZQ calibration) command. Register DDRCTL_DBGCMD.zq_calib_short can be used instead to issue ZQ calibration request from APB module.
  [30] DIS_SRX_ZQCL — 1 - Disable issuing of ZQCL/MPC(ZQ calibration) command at Self-Refresh/SR-Powerdown exit. Only applicable when run in DDR3 or DDR4 or LPDDR2 or LPDDR3 or LPDDR4 mode.
  [29] ZQ_RESISTOR_SHARED — 1 - Denotes that ZQ resistor is shared between ranks. Means ZQinit/ZQCL/ZQCS/MPC(ZQ calibration) commands are sent to one rank at a time with tZQinit/tZQCL/tZQCS/tZQCAL/tZQLAT timing met between commands so that commands to different ranks do not overlap.
  [28] DIS_MPSMX_ZQCL — 1 - Disable issuing of ZQCL command at Maximum Power Saving Mode exit. Only applicable when run in DDR4 mode.
  [26:16] T_ZQ_LONG_NOP — tZQoper for DDR3/DDR4, tZQCL for LPDDR2/LPDDR3, tZQCAL for LPDDR4: Number of DDRSS_CTL_CLK clock cycles of NOP required after a ZQCL (ZQ calibration long)/MPC(ZQ Start) command is issued to SDRAM.DDR3/DDR4: program this to tZQoper/2 and round it up to the next integer value.LPDDR2/LPDDR3: program this to tZQCL/2 and round it up to the next integer value.LPDDR4: program this to tZQCAL/2 and round it up to the next integer value.This is only present for designs supporting DDR3/DDR4 or LPDDR2/LPDDR3/LPDDR4 devices.
  [9:0] T_ZQ_SHORT_NOP — tZQCS for DDR3/DD4/LPDDR2/LPDDR3, tZQLAT for LPDDR4: Number of DDRSS_CTL_CLK clock cycles of NOP required after a ZQCS (ZQ calibration short)/MPC(ZQ Latch) command is issued to SDRAM.
0x184 DDRCTL_ZQCTL1 reset 0x2000100 — ZQ Control Register 1
  [29:20] T_ZQ_RESET_NOP — tZQReset: Number of DDRSS_CTL_CLK clock cycles of NOP required after a ZQReset (ZQ calibration Reset) command is issued to SDRAM.
  [19:0] T_ZQ_SHORT_INTERVAL_X1024 — Average interval to wait between automatically issuing ZQCS (ZQ calibration short)/MPC(ZQ calibration) commands to DDR3/DDR4/LPDDR2/LPDDR3/LPDDR4 devices.
0x188 DDRCTL_ZQCTL2 access not given — ZQ Control Register 2
  [0] ZQ_RESET — Setting this register bit to 1 triggers a ZQ Reset operation. (access W1S)
0x18C DDRCTL_ZQSTAT ro — ZQ Status Register
  [0] ZQ_RESET_BUSY — SoC core may initiate a ZQ Reset operation only if this signal is low.
0x190 DDRCTL_DFITMG0 reset 0x7020002 — DFI Timing Register 0
  [28:24] DFI_T_CTRL_DELAY — Specifies the number of DDRSS_CTL_CLK clock cycles after an assertion or de-assertion of the DFI control signals that the control signals at the PHY-DRAM interface reflect the assertion or de-assertion.
  [23] DFI_RDDATA_USE_DFI_PHY_CLK — Defines whether dfi_rddata_en/dfi_rddata/dfi_rddata_valid is generated using HDR (DDRSS_CTL_CLK clock) or SDR (2 x DDRSS_CTL_CLK clock) values.- 0 in terms of HDR (DDRSS_CTL_CLK clock) cycles- 1 in terms of SDR (2 x DDRSS_CTL_CLK clock) cyclesIf using a DWC DDR3/2 PHY, DWC DDR2/3-Lite/mDDR PHY, DWC DDR multiPHY or DWC Gen2 DDR multiPHY, this field must be set to 0, otherwise it must be set to 1.Programming Mode: Static
  [22:16] DFI_T_RDDATA_EN — Time from the assertion of a read command on the DFI interface to the assertion of the dfi_rddata_en signal.
  [15] DFI_WRDATA_USE_DFI_PHY_CLK — Defines whether dfi_wrdata_en/dfi_wrdata/dfi_wrdata_mask is generated using HDR (DDRSS_CTL_CLK clock) or SDR (2 x DDRSS_CTL_CLK clock) values. Selects whether value in DDRCTL_DFITMG0.dfi_tphy_wrlat is in terms of HDR (DDRSS_CTL_CLK clock) or SDR (2 x DDRSS_CTL_CLK clock) cyclesSelects whether value in DDRCTL_DFITMG0.dfi_tphy_wrdata is in terms of HDR (DDRSS_CTL_CLK clock) or SDR (2 x DDRSS_CTL_CLK clock) cycles- 0 in terms of HDR (DDRSS_CTL_CLK clock) cycles- 1 in terms of SDR (2 x DDRSS_CTL_CLK clock) cyclesIf using a DWC DDR3/2 PHY, DWC DDR2/3-Lite/mDDR PHY, DWC DDR multiPHY or DWC Gen2 DDR multiPHY, this field must be set to 0, otherwise it must be set to 1.Programming Mode: Static
  [13:8] DFI_TPHY_WRDATA — Specifies the number of clock cycles between when dfi_wrdata_en is asserted to when the associated write data is driven on the dfi_wrdata signal.
  [5:0] DFI_TPHY_WRLAT — Write latency Number of clocks from the write command to write data enable (dfi_wrdata_en).
